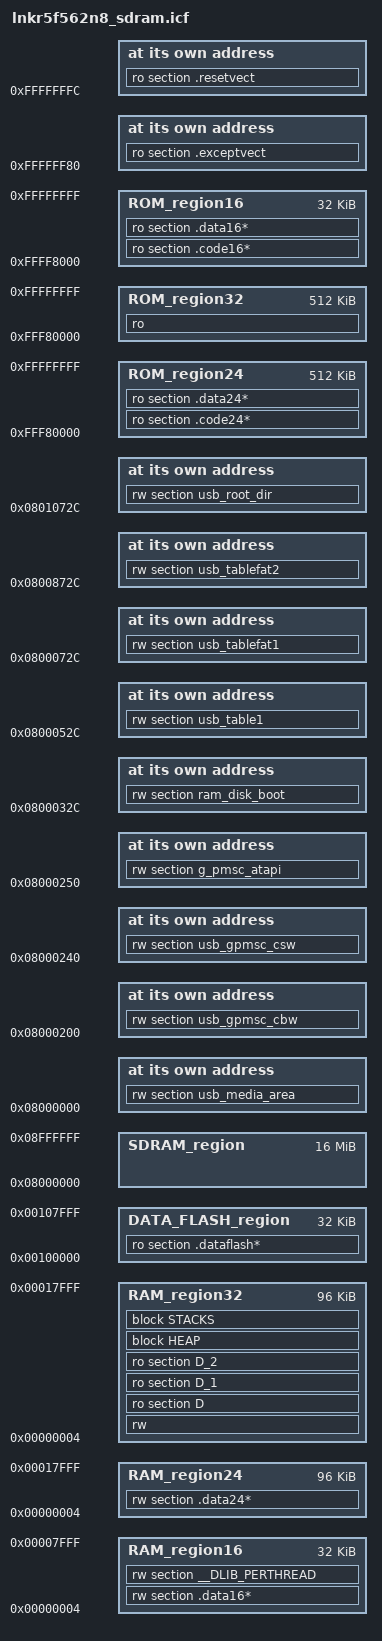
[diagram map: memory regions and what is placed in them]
//-----------------------------------------------------------------------------
// Linker configuration file template for the Renesas RX microcontroller R5F562N8
//-----------------------------------------------------------------------------
// Compatibility check
define exported symbol __link_file_version_4 = 1;

define memory mem with size = 4G;

define region ROM_region16 = mem:[from 0xFFFF8000 to 0xFFFFFFFF];
define region RAM_region16 = mem:[from 0x00000004 to 0x00007FFF];
define region ROM_region24 = mem:[from 0xFFF80000 to 0xFFFFFFFF];
define region RAM_region24 = mem:[from 0x00000004 to 0x00017FFF];
define region ROM_region32 = mem:[from 0xFFF80000 to 0xFFFFFFFF];
define region RAM_region32 = mem:[from 0x00000004 to 0x00017FFF];

define region DATA_FLASH_region = mem:[from 0x00100000 to 0x00107FFF];
define region SDRAM_region = mem:[from 0x08000000 to 0x08FFFFFF];

initialize by copy { rw, ro section D, ro section D_1, ro section D_2,
                     rw section usb_media_area, rw section g_pmsc_atapi };

do not initialize  { section .*.noinit };

define block HEAP     with alignment = 4, size = _HEAP_SIZE { };
define block USTACK   with alignment = 4, size = _USTACK_SIZE { };
define block ISTACK   with alignment = 4, size = _ISTACK_SIZE { };

define block STACKS with fixed order { block ISTACK,
                                       block USTACK };

place at address mem:0xFFFFFFFC { ro section .resetvect };
place at address mem:0xFFFFFF80 { ro section .exceptvect };

"ROM16":place in ROM_region16        { ro section .code16*,
                                       ro section .data16* };
"RAM16":place in RAM_region16        { rw section .data16*,
                                       rw section __DLIB_PERTHREAD };
"ROM24":place in ROM_region24        { ro section .code24*,
                                       ro section .data24* };
"RAM24":place in RAM_region24        { rw section .data24* };
"ROM32":place in ROM_region32        { ro };
"RAM32":place in RAM_region32        { rw,
                                       ro section D,
                                       ro section D_1,
                                       ro section D_2,
                                       block HEAP,
                                       block STACKS };

"DATAFLASH":place in DATA_FLASH_region
                                     { ro section .dataflash* };


"SDRAM":place at address mem:0x08000000 { rw section usb_media_area };
"SDRAM":place at address mem:0x08000200 { rw section usb_gpmsc_cbw };
"SDRAM":place at address mem:0x08000240 { rw section usb_gpmsc_csw };
"SDRAM":place at address mem:0x08000250 { rw section g_pmsc_atapi };
"SDRAM":place at address mem:0x0800032c { rw section ram_disk_boot };
"SDRAM":place at address mem:0x0800052c { rw section usb_table1 };
"SDRAM":place at address mem:0x0800072c { rw section usb_tablefat1 };
"SDRAM":place at address mem:0x0800872c { rw section usb_tablefat2 };
"SDRAM":place at address mem:0x0801072c { rw section usb_root_dir };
